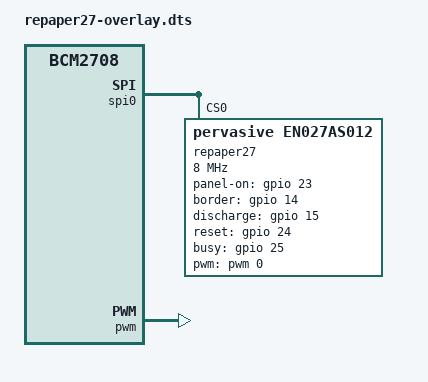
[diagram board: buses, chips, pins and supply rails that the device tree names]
/*

This display won't work on the Raspberry Pi without a change to pwm-bcm2835:
Don't set the PWM_MODE bit in bcm2835_pwm_request()

diff --git a/drivers/pwm/pwm-bcm2835.c b/drivers/pwm/pwm-bcm2835.c
index c5dbf16..5d91690 100644
--- a/drivers/pwm/pwm-bcm2835.c
+++ b/drivers/pwm/pwm-bcm2835.c
@@ -43,10 +43,12 @@ static int bcm2835_pwm_request(struct pwm_chip *chip, struct pwm_device *pwm)
        struct bcm2835_pwm *pc = to_bcm2835_pwm(chip);
        u32 value;

+       if (0) {
        value = readl(pc->base + PWM_CONTROL);
        value &= ~(PWM_CONTROL_MASK << PWM_CONTROL_SHIFT(pwm->hwpwm));
        value |= (PWM_MODE << PWM_CONTROL_SHIFT(pwm->hwpwm));
        writel(value, pc->base + PWM_CONTROL);
+       }

        return 0;
 }

*/

/dts-v1/;
/plugin/;

/ {
	compatible = "brcm,bcm2708";

	fragment@0 {
		target = <&spi0>;
		__overlay__ {
			status = "okay";

			spidev@0{
				status = "disabled";
			};
		};
	};

	fragment@1 {
		target = <&gpio>;
		__overlay__ {
			repaper27_pins: repaper27_pins {
				brcm,pins = <14 15 23 24 25 18>;
				brcm,function = <1 1 1 1 0 2>; /* out out out out in alt5 */
			};
		};
	};

	fragment@2 {
		target = <&pwm>;
		__overlay__ {
			status = "okay";

			assigned-clock-rates = <100000>;
		};
	};

	fragment@3 {
		target = <&spi0>;
		__overlay__ {
			/* needed to avoid dtc warning */
			#address-cells = <1>;
			#size-cells = <0>;

			repaper27: repaper27@0{
				compatible = "pervasive,en027as012";
				reg = <0>;
				pinctrl-names = "default";
				pinctrl-0 = <&repaper27_pins>;

				spi-max-frequency = <8000000>;

				panel-on-gpios = <&gpio 23 0>;
				border-gpios = <&gpio 14 0>;
				discharge-gpios = <&gpio 15 0>;
				reset-gpios = <&gpio 24 0>;
				busy-gpios = <&gpio 25 0>;

				pwms = <&pwm 0 10240000 0>;
				pwm-names = "pwm";
			};
		};
	};

	__overrides__ {
		speed =    <&repaper27>, "spi-max-frequency:0";
	};
};
